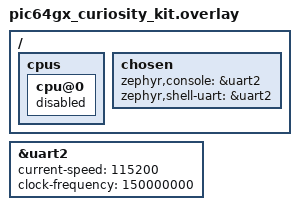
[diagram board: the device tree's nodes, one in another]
/ {
	cpus {
		cpu@0 {
			status = "disabled";
		};
	};

	chosen {
		zephyr,console = &uart2;
		zephyr,shell-uart = &uart2;
	};
};

&uart2 {
	status = "okay";
	current-speed = <115200>;
	clock-frequency = <150000000>;
};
